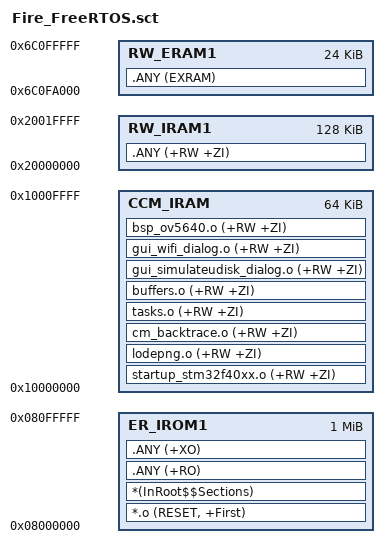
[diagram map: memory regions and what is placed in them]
; *************************************************************
; *** Scatter-Loading Description File generated by uVision ***
; *************************************************************

LR_IROM1 0x08000000 0x00100000  {    ; load region size_region
  ER_IROM1 0x08000000 0x00100000  {  ; load address = execution address
   *.o (RESET, +First)
   *(InRoot$$Sections)
   .ANY (+RO)
   .ANY (+XO)
  }
  RW_IRAM1 0x20000000 0x00020000  {  ; 内部SRAM 
  .ANY (+RW +ZI)      ;其余的RW/ZI-data都分配到这里
  }
   
  RW_ERAM1 0x6C0FA000 0x0000006000 {  ; 外部SDRAM
;  *.o(HEAP)            ;选择堆区
  .ANY (EXRAM)       ;选择EXRAM节区
  }
  CCM_IRAM 0x10000000 0x00010000  {  ; 内部CCM 只能内核访问  
;  heap_4.o (+RW +ZI)      ;将外设不访问的数据分配到这里
   startup_stm32f40xx.o       (+RW +ZI)
   lodepng.o                  (+RW +ZI)   
   cm_backtrace.o             (+RW +ZI)      
   tasks.o                    (+RW +ZI)      
   buffers.o                  (+RW +ZI) 
   gui_simulateudisk_dialog.o (+RW +ZI)     
   gui_wifi_dialog.o          (+RW +ZI) 
   bsp_ov5640.o               (+RW +ZI)
  }
  
}

